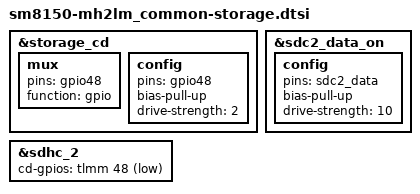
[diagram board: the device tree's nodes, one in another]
/*
 * Copyright (c) 2018, The Linux Foundation. All rights reserved.
 *
 * This program is free software; you can redistribute it and/or modify
 * it under the terms of the GNU General Public License version 2 and
 * only version 2 as published by the Free Software Foundation.
 *
 * This program is distributed in the hope that it will be useful,
 * but WITHOUT ANY WARRANTY; without even the implied warranty of
 * MERCHANTABILITY or FITNESS FOR A PARTICULAR PURPOSE.  See the
 * GNU General Public License for more details.
 */
#include "../../sm8150_common/sm8150_common-storage.dtsi"

&storage_cd {
    mux {
        pins = "gpio48";
        function = "gpio";
    };

    config {
        pins = "gpio48";
        bias-pull-up;           /* pull up */
        drive-strength = <2>;   /* 2 MA */
    };
};

&sdc2_data_on {
	config {
		pins = "sdc2_data";
		bias-pull-up;           /* pull up */
		drive-strength = <10>;  /* 10 MA */
	};
};

&sdhc_2 {
	cd-gpios = <&tlmm 48 GPIO_ACTIVE_LOW>;
};
